# STM32G0C1xx register map
File version: 1.0
Registers are 32-bit, read-write, reset 0x0 unless marked. A register's access mark holds for its fields unless they carry their own. Offsets are from the block's base; [hi:lo] are bit positions.

## CEC — HDMI-CEC
Base 0x40007800
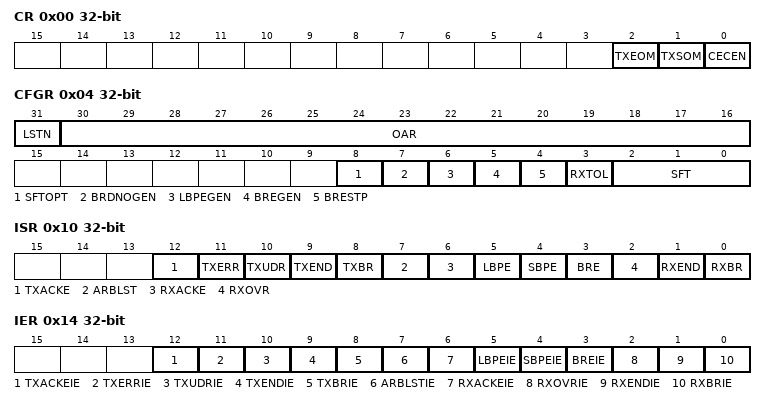
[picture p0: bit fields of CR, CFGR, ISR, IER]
0x00 CR — CEC control register
  [2] TXEOM — CEC Tx End Of Message
  [1] TXSOM — CEC Tx Start Of Message
  [0] CECEN — CEC Enable
0x04 CFGR — CEC configuration register
  [31] LSTN — CEC Listen mode
  [30:16] OAR — CEC Own Address
  [8] SFTOPT — CEC Signal Free Time optional
  [7] BRDNOGEN — CEC Broadcast No Error generation
  [6] LBPEGEN — CEC Long Bit Period Error gener
  [5] BREGEN — CEC Bit Rising Error generation
  [4] BRESTP — CEC Rx Stop
  [3] RXTOL — CEC Tolerance
  [2:0] SFT — CEC Signal Free Time
0x08 TXDR — CEC Tx data register
  [7:0] TXD — CEC Tx Data
0x0C RXDR — CEC Rx Data Register
  [7:0] RXD — CEC Rx Data
0x10 ISR — CEC Interrupt and Status Register
  [12] TXACKE — CEC Tx Missing Acknowledge
  [11] TXERR — CEC Tx-Error
  [10] TXUDR — CEC Tx-Buffer Underrun
  [9] TXEND — CEC End of Transmission
  [8] TXBR — CEC Tx Byte Request
  [7] ARBLST — CEC Arbitration Lost
  [6] RXACKE — CEC Rx Missing Acknowledge
  [5] LBPE — CEC Rx Long Bit period Error
  [4] SBPE — CEC Rx Short Bit period Error
  [3] BRE — CEC Rx Bit Rising Error
  [2] RXOVR — CEC Rx-Overrun
  [1] RXEND — CEC End Of Reception
  [0] RXBR — CEC Rx-Byte Received
0x14 IER — CEC interrupt enable register
  [12] TXACKEIE — CEC Tx Missing Acknowledge IT Enable
  [11] TXERRIE — CEC Tx-Error IT Enable
  [10] TXUDRIE — CEC Tx-Buffer Underrun IT Enable
  [9] TXENDIE — CEC End of Transmission IT Enable
  [8] TXBRIE — CEC Tx Byte Request IT Enable
  [7] ARBLSTIE — CEC Arbitration Lost IT Enable
  [6] RXACKEIE — CEC Rx Missing Acknowledge IT Enable
  [5] LBPEIE — CEC Rx Long Bit period Error IT Enable
  [4] SBPEIE — CEC Rx Short Bit period Error IT Enable
  [3] BREIE — CEC Rx Bit Rising Error IT Enable
  [2] RXOVRIE — CEC Rx-Overrun IT Enable
  [1] RXENDIE — CEC End Of Reception IT Enable
  [0] RXBRIE — CEC Rx-Byte Received IT Enable

## I2C3 — Inter-integrated Circuit Interface
Base 0x40008800
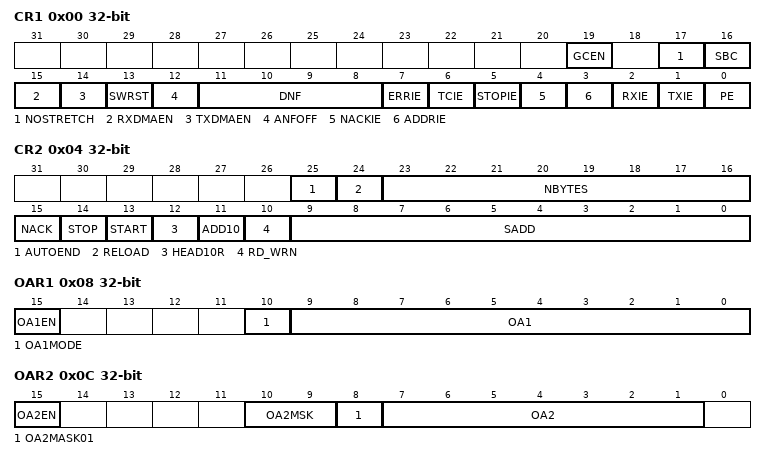
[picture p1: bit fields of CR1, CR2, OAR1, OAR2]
0x00 CR1 — I2C Control register 1
  [19] GCEN — General call enable
  [17] NOSTRETCH — Clock stretching disable
  [16] SBC — Slave byte control
  [15] RXDMAEN — DMA reception requests enable
  [14] TXDMAEN — DMA transmission requests enable
  [13] SWRST — Software reset
  [12] ANFOFF — Analog noise filter OFF
  [11:8] DNF — Digital noise filter
  [7] ERRIE — Errors interrupt enable
  [6] TCIE — Transfer complete interrupt enable
  [5] STOPIE — STOP detection interrupt enable
  [4] NACKIE — NACK received interrupt enable
  [3] ADDRIE — Address match interrupt enable
  [2] RXIE — RX interrupt enable
  [1] TXIE — TX interrupt enable
  [0] PE — Peripheral enable
0x04 CR2 — I2C Control register 2
  [25] AUTOEND — Automatic end mode (master mode)
  [24] RELOAD — NBYTES reload mode
  [23:16] NBYTES — Number of bytes
  [15] NACK — NACK generation (slave mode)
    0=ACK (ACK is sent after current received byte.); 1=NACK (NACK is sent after current received byte.)
  [14] STOP — STOP generation (master mode)
  [13] START — START generation
  [12] HEAD10R — 10-bit address header only read direction (master mode)
  [11] ADD10 — 10-bit addressing mode (master mode)
    0=MODE_7BIT (Master operates in 7-bit addressing mode.); 1=MODE_10BIT (Master operates in 10-bit addressing mode.)
  [10] RD_WRN — Transfer direction (master mode)
    0=WRITE (Master request a write transfer.); 1=READ (Master request a read transfer.)
  [9:0] SADD — Slave address (master mode)
0x08 OAR1 — I2C Own address 1 register
  [15] OA1EN — Own address 1 enable
  [10] OA1MODE — Own address 1 10-bit mode
  [9:0] OA1 — Interface own address 1
0x0C OAR2 — I2C Own address 2 register
  [15] OA2EN — Own address 2 enable
  [10:9] OA2MSK — Own address 2 masks
  [8] OA2MASK01 — OA2[1] is masked, Only OA2[7:2] are compared
  [7:1] OA2 — Interface own address 2
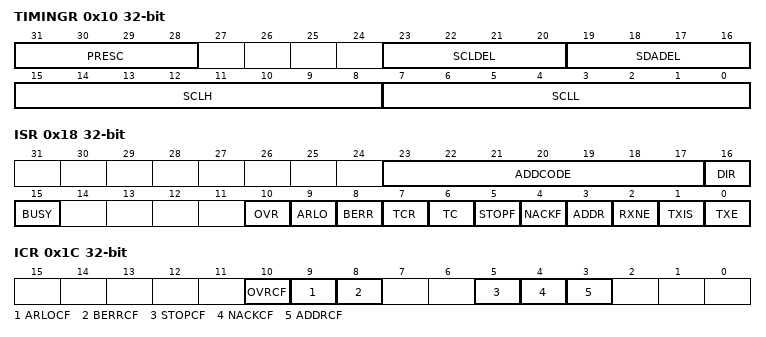
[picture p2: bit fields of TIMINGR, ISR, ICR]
0x10 TIMINGR — I2C Timing register
  [31:28] PRESC — Timings prescaler
  [23:20] SCLDEL — Data setup time
  [19:16] SDADEL — Data hold time
  [15:8] SCLH — SCL high period (master mode)
  [7:0] SCLL — SCL low period (master mode)
0x18 ISR — I2C Interrupt and status register
  [23:17] ADDCODE — Address match code (slave mode)
  [16] DIR — Transfer direction (slave mode)
    0=WRITE; 1=READ
  [15] BUSY — Bus busy
  [10] OVR — Overrun/Underrun
  [9] ARLO — Arbitration lost
  [8] BERR — Bus error
  [7] TCR — Transfer complete reload
  [6] TC — Transfer complete (master mode)
  [5] STOPF — STOP detection flag
  [4] NACKF — NACK received flag
  [3] ADDR — Address matched (slave mode)
  [2] RXNE — Receive data register not empty
  [1] TXIS — Transmit interrupt status
  [0] TXE — Transmit data register empty
0x1C ICR — I2C Interrupt clear register
  [10] OVRCF — Overrun/Underrun clear flag
  [9] ARLOCF — Arbitration lost clear flag
  [8] BERRCF — Bus error clear flag
  [5] STOPCF — STOP detection clear flag
  [4] NACKCF — NACK clear flag
  [3] ADDRCF — Address matched clear flag
0x24 RXDR — I2C Receive data register
  [7:0] RXDATA — 8-bit receive data
0x28 TXDR — I2C Transmit data register
  [7:0] TXDATA — 8-bit transmit data
